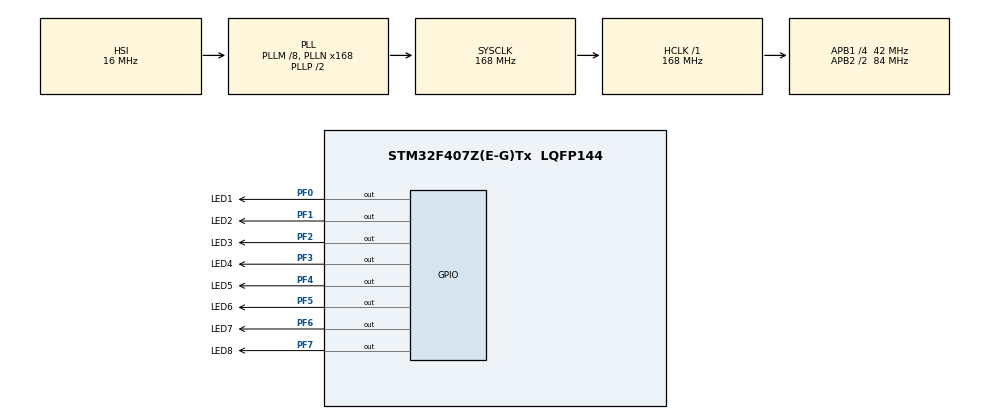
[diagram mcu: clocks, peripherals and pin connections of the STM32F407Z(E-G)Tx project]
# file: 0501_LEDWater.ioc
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Mcu.Family=STM32F4
Mcu.Name=STM32F407Z(E-G)Tx
Mcu.Package=LQFP144
NVIC.PriorityGroup=NVIC_PRIORITYGROUP_4
PA13.Mode=Serial_Wire
PA13.Signal=SYS_JTMS-SWDIO
PA14.Mode=Serial_Wire
PA14.Signal=SYS_JTCK-SWCLK
PC14-OSC32_IN.Mode=LSE-External-Oscillator
PC14-OSC32_IN.Signal=RCC_OSC32_IN
PC15-OSC32_OUT.Mode=LSE-External-Oscillator
PC15-OSC32_OUT.Signal=RCC_OSC32_OUT
PF0.GPIO_Label=LED1
PF0.PinState=GPIO_PIN_SET
PF0.Signal=GPIO_Output
PF1.GPIO_Label=LED2
PF1.PinState=GPIO_PIN_SET
PF1.Signal=GPIO_Output
PF2.GPIO_Label=LED3
PF2.PinState=GPIO_PIN_SET
PF2.Signal=GPIO_Output
PF3.GPIO_Label=LED4
PF3.PinState=GPIO_PIN_SET
PF3.Signal=GPIO_Output
PF4.GPIO_Label=LED5
PF4.PinState=GPIO_PIN_SET
PF4.Signal=GPIO_Output
PF5.GPIO_Label=LED6
PF5.PinState=GPIO_PIN_SET
PF5.Signal=GPIO_Output
PF6.GPIO_Label=LED7
PF6.PinState=GPIO_PIN_SET
PF6.Signal=GPIO_Output
PF7.GPIO_Label=LED8
PF7.PinState=GPIO_PIN_SET
PF7.Signal=GPIO_Output
PH0-OSC_IN.Mode=HSE-External-Oscillator
PH0-OSC_IN.Signal=RCC_OSC_IN
PH1-OSC_OUT.Mode=HSE-External-Oscillator
PH1-OSC_OUT.Signal=RCC_OSC_OUT
ProjectManager.HeapSize=0x200
ProjectManager.StackSize=0x400
ProjectManager.TargetToolchain=STM32CubeIDE
RCC.48MHZClocksFreq_Value=48000000
RCC.AHBFreq_Value=168000000
RCC.APB1CLKDivider=RCC_HCLK_DIV4
RCC.APB1Freq_Value=42000000
RCC.APB1TimFreq_Value=84000000
RCC.APB2CLKDivider=RCC_HCLK_DIV2
RCC.APB2Freq_Value=84000000
RCC.APB2TimFreq_Value=168000000
RCC.CortexFreq_Value=168000000
RCC.HCLKFreq_Value=168000000
RCC.HSE_VALUE=8000000
RCC.HSI_VALUE=16000000
RCC.PLLM=8
RCC.PLLN=168
RCC.PLLQ=7
RCC.SYSCLKFreq_VALUE=168000000
RCC.SYSCLKSource=RCC_SYSCLKSOURCE_PLLCLK
RCC.VCOOutputFreq_Value=336000000
board=custom

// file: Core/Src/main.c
/* USER CODE BEGIN Header */
/**
  ******************************************************************************
  * @file           : main.c
  * @brief          : 实验一（新版）：LED 流水灯 —— 定时器帧驱动
  ******************************************************************************
  * @attention
  *
  * 动画完全由 TIM7 中断推进，主循环只需要睡下去：
  *   初始化 → 启动效果引擎 → while(1) 里 __WFI() 等待中断唤醒。
  * 想改效果只要改 led_engine.c 里的帧表，不用碰主循环。
  *
  ******************************************************************************
  */
/* USER CODE END Header */
#include "main.h"
#include "gpio.h"

/* USER CODE BEGIN Includes */
#include "led_engine.h"
/* USER CODE END Includes */

void SystemClock_Config(void);

int main(void)
{

  /* MCU Configuration--------------------------------------------------------*/

  /* Reset of all peripherals, Initializes the Flash interface and the Systick. */
  HAL_Init();

  /* Configure the system clock */
  SystemClock_Config();

  /* Initialize all configured peripherals */
  MX_GPIO_Init();
  /* USER CODE BEGIN 2 */
  LED_Engine_Init();          /* 配置 TIM7 并开始播放动画 */
  /* USER CODE END 2 */

  /* Infinite loop */
  /* USER CODE BEGIN WHILE */
  while (1)
  {
    /* 所有工作都在 TIM7 中断里完成，这里直接进入低功耗等待。
       __WFI() 会在任意中断到来时被唤醒，处理完继续睡。 */
    __WFI();
    /* USER CODE END WHILE */

  }
}

void SystemClock_Config(void)
{
  RCC_OscInitTypeDef RCC_OscInitStruct = {0};
  RCC_ClkInitTypeDef RCC_ClkInitStruct = {0};

  /** Configure the main internal regulator output voltage
  */
  __HAL_RCC_PWR_CLK_ENABLE();
  __HAL_PWR_VOLTAGESCALING_CONFIG(PWR_REGULATOR_VOLTAGE_SCALE1);

  /** Initializes the RCC Oscillators according to the specified parameters
  * in the RCC_OscInitTypeDef structure.
  */
  RCC_OscInitStruct.OscillatorType = RCC_OSCILLATORTYPE_HSI;
  RCC_OscInitStruct.HSIState = RCC_HSI_ON;
  RCC_OscInitStruct.HSICalibrationValue = RCC_HSICALIBRATION_DEFAULT;
  RCC_OscInitStruct.PLL.PLLState = RCC_PLL_ON;
  RCC_OscInitStruct.PLL.PLLSource = RCC_PLLSOURCE_HSI;
  RCC_OscInitStruct.PLL.PLLM = 8;
  RCC_OscInitStruct.PLL.PLLN = 168;
  RCC_OscInitStruct.PLL.PLLP = RCC_PLLP_DIV2;
  RCC_OscInitStruct.PLL.PLLQ = 7;
  if (HAL_RCC_OscConfig(&RCC_OscInitStruct) != HAL_OK)
  {
    Error_Handler();
  }

  /** Initializes the CPU, AHB and APB buses clocks
  */
  RCC_ClkInitStruct.ClockType = RCC_CLOCKTYPE_HCLK|RCC_CLOCKTYPE_SYSCLK
                              |RCC_CLOCKTYPE_PCLK1|RCC_CLOCKTYPE_PCLK2;
  RCC_ClkInitStruct.SYSCLKSource = RCC_SYSCLKSOURCE_PLLCLK;
  RCC_ClkInitStruct.AHBCLKDivider = RCC_SYSCLK_DIV1;
  RCC_ClkInitStruct.APB1CLKDivider = RCC_HCLK_DIV4;
  RCC_ClkInitStruct.APB2CLKDivider = RCC_HCLK_DIV2;

  if (HAL_RCC_ClockConfig(&RCC_ClkInitStruct, FLASH_LATENCY_5) != HAL_OK)
  {
    Error_Handler();
  }
}

void Error_Handler(void)
{
  __disable_irq();
  while (1)
  {
  }
}
